# haltium_cellrf register map
Vendor: Nordic Semiconductor; Series: nRFHaltium; File version: 1
CPU: CM0 r0p0, little endian, no MPU, no FPU, 2 interrupt priority bits, 33 interrupts
Registers are 32-bit, read-write, reset 0x0 unless marked. A register's access mark holds for its fields unless they carry their own. Offsets are from the block's base; [hi:lo] are bit positions; lines under a group give offsets from that group; {n}, {i} and the like mark numbered series; 'fields as' and 'values as' point back to an identical list.

## MEMCONF — Memory configuration
Base 0x46014000
{0x500+0x10*i} POWER[{i}] (i=0..3) group — Unspecified
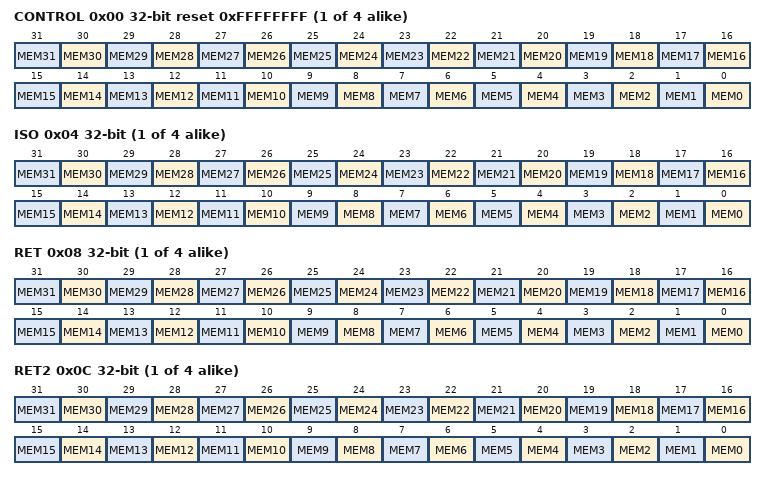
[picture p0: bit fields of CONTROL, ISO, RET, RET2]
  0x00 CONTROL reset 0xFFFFFFFF — Description cluster: RAM/ROM[n] power control register.
    [all] fields
      0=Off (Power down); 1=On (Power up)
    [n] MEM{n} (n=0..31) — Keep the RAM/ROM block MEM[{n}] on or off when in System ON mode.
  0x04 ISO — Description cluster: RAM/ROM [n] power isolation control register.
    [all] fields
      0=Off (Isolation off); 1=On (Isolation on)
    [n] MEM{n} (n=0..31) — Turn on/off the power isolation for RAM/ROM block MEM[{n}].
  0x08 RET — Description cluster: RAM retention for RAM/ROM [n].
    [all] fields
      0=Off (Retention off); 1=On (Retention on)
    [n] MEM{n} (n=0..31) — Keep the RAM block MEM[{n}] retained when in System OFF mode.
  0x0C RET2 — Description cluster: RAM retention for the second bank in the RAM block
    [all] fields
      0=Off (Retention off); 1=On (Retention on)
    [n] MEM{n} (n=0..31) — Keep the second bank in RAM block MEM[{n}] retained when in System OFF mode.
{0x600+4i} REPAIR[{i}] (i=0..191) group — Unspecified
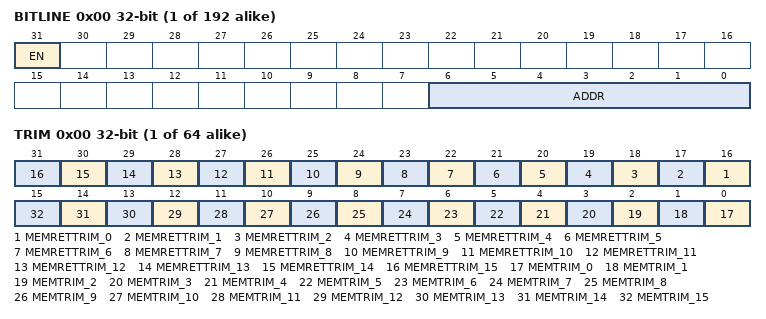
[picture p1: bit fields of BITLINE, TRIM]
  0x00 BITLINE — Description cluster: Repair configuration for RAM/ROM blocks.
    [31] EN — Enable bitline repair
      0=Disabled (Repair disabled.); 1=Enabled (Repair enabled.)
    [6:0] ADDR — Repair address of the bitline
{0x900+4i} BLOCKTYPE[{i}] (i=0..63) group — Unspecified
  0x00 TRIM — Description cluster: Trim configuration for the RAM/ROM block types.
    [n+16] MEMRETTRIM_{n} (n=0..15) — Trimming for retention mode for decreased leakage. Must be kept active in RAM retention mode.
    [n] MEMTRIM_{n} (n=0..15) — Read/write margin trim.

## BELLBOARD — BELLBOARD APB registers
Base 0x4F09E000
{0x0+4i} TASKS_TRIGGER[{i}] (i=0..31) wo — Description collection: Task TRIGGER[n]
  [0] TASKS_TRIGGER — Task TRIGGER[n]
    1=Trigger task
{0x100+4i} EVENTS_TRIGGERED[{i}] (i=0..31) — Description collection: Event TRIGGERED[n]
  [0] EVENTS_TRIGGERED — Event TRIGGERED[n]
    0=NotGenerated (Event not generated); 1=Generated (Event generated)
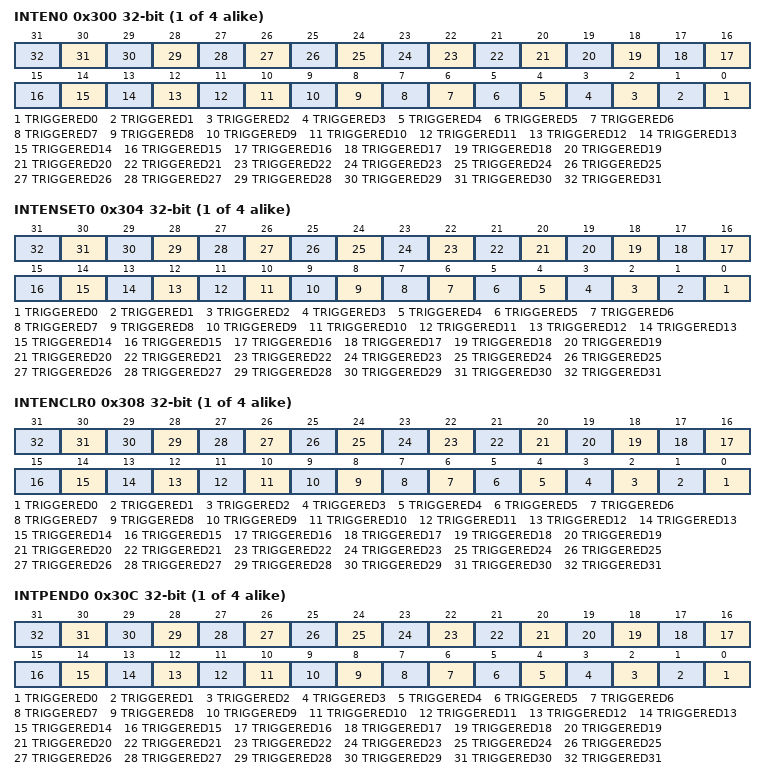
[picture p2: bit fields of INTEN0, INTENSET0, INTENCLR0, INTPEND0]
{0x300+0x10*i} INTEN{i} (i=0..3) — Enable or disable interrupt
  [all] fields
    0=Disabled; 1=Enabled
  [n] TRIGGERED{n} (n=0..31) — Enable or disable interrupt for event TRIGGERED[{n}]
{0x304+0x10*i} INTENSET{i} (i=0..3) — Enable interrupt
  [all] fields
    on read: 0=Disabled (Read: Disabled); 1=Enabled (Read: Enabled) | on write: 1=Set (Enable)
  [n] TRIGGERED{n} (n=0..31) — Write '1' to enable interrupt for event TRIGGERED[{n}]
{0x308+0x10*i} INTENCLR{i} (i=0..3) — Disable interrupt
  [all] fields
    on read: 0=Disabled (Read: Disabled); 1=Enabled (Read: Enabled) | on write: 1=Clear (Disable)
  [n] TRIGGERED{n} (n=0..31) — Write '1' to disable interrupt for event TRIGGERED[{n}]
{0x30C+0x10*i} INTPEND{i} ro (i=0..3) — Pending interrupts
  [all] fields
    on read: 0=NotPending (Read: Not pending); 1=Pending (Read: Pending)
  [n] TRIGGERED{n} (n=0..31) — Read pending status of interrupt for event TRIGGERED[{n}]

## DPPIC — Distributed programmable peripheral interconnect controller 0
Base 0x46050000
Same registers: GLOBAL_DPPIC120 0x5F8E1000, GLOBAL_DPPIC130 0x5F922000, GLOBAL_DPPIC131 0x5F981000, GLOBAL_DPPIC132 0x5F991000, GLOBAL_DPPIC133 0x5F9A1000, GLOBAL_DPPIC134 0x5F9B1000, GLOBAL_DPPIC135 0x5F9C1000, GLOBAL_DPPIC136 0x5F9D1000
{0x0+8i} TASKS_CHG[{i}] (i=0..1) group — Channel group tasks
  0x00 EN wo — Description cluster: Enable channel group n
    [0] EN — Enable channel group n
      1=Trigger task
  0x04 DIS wo — Description cluster: Disable channel group n
    [0] DIS — Disable channel group n
      1=Trigger task
{0x80+8i} SUBSCRIBE_CHG[{i}] (i=0..1) group — Subscribe configuration for tasks
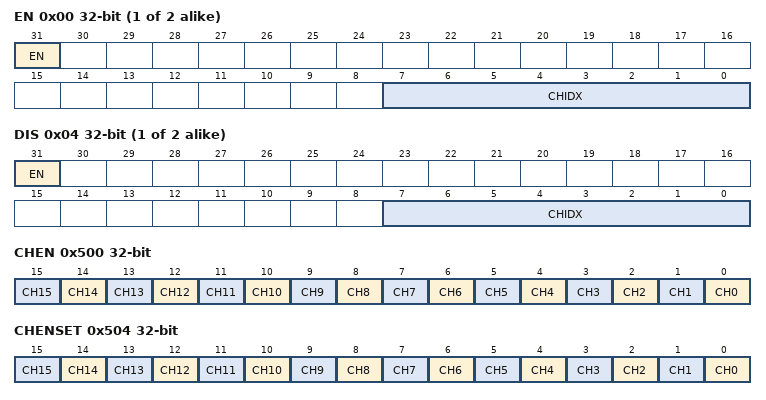
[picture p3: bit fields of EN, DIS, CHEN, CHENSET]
  0x00 EN — Description cluster: Subscribe configuration for task CHG[n].EN
    [31] EN
      0=Disabled (Disable subscription); 1=Enabled (Enable subscription)
    [7:0] CHIDX — DPPI channel that task CHG[n].EN will subscribe to
  0x04 DIS — Description cluster: Subscribe configuration for task CHG[n].DIS
    [31] EN
      values as SUBSCRIBE_CHG[0].EN.EN
    [7:0] CHIDX — DPPI channel that task CHG[n].DIS will subscribe to
0x500 CHEN — Channel enable register
  [all] fields
    0=Disabled (Disable channel); 1=Enabled (Enable channel)
  [n] CH{n} (n=0..15) — Enable or disable channel {n}
0x504 CHENSET write-1-sets — Channel enable set register
  [all] fields
    on read: 0=Disabled (Read: Channel disabled); 1=Enabled (Read: Channel enabled) | on write: 1=Set (Write: Enable channel)
  [n] CH{n} (n=0..15) — Channel {n} enable set register. Writing 0 has no effect.
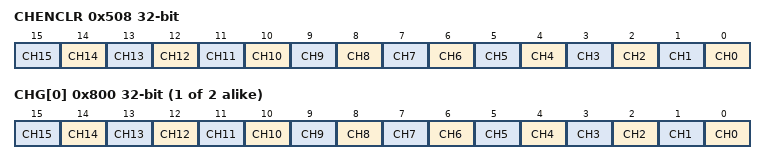
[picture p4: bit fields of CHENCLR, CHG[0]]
0x508 CHENCLR write-1-clears — Channel enable clear register
  [all] fields
    on read: 0=Disabled (Read: Channel disabled); 1=Enabled (Read: Channel enabled) | on write: 1=Clear (Write: Disable channel)
  [n] CH{n} (n=0..15) — Channel {n} enable clear register. Writing 0 has no effect.
{0x800+4i} CHG[{i}] (i=0..1) — Description collection: Channel group n Note: Writes to this register are ignored if either SUBSCRIBE_CHG[n].EN or SUBSCRIBE_CHG[n].DIS is enabled
  [all] fields
    0=Excluded; 1=Included
  [n] CH{n} (n=0..15) — Include or exclude channel {n}
